# LKS32MC03x register map
Vendor: Linko Ltd.; Series: LKS32MC03x; File version: 1.0
CPU: CM0 r1p0, little endian, MPU, no FPU, 3 interrupt priority bits
Registers are 32-bit, read-write, reset 0x0 unless marked. A register's access mark holds for its fields unless they carry their own. Offsets are from the block's base; [hi:lo] are bit positions; {n}, {i} and the like mark numbered series.

## I2C — I2C registers
Base 0x40010100
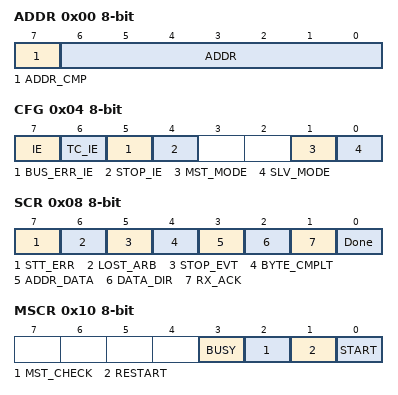
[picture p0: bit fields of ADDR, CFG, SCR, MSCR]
0x00 ADDR 8-bit — I2C Device Address
  [7] ADDR_CMP — i2c address compared by hardware control bit
    0=DISABLED (disable address compare by hardware); 1=ENABLED (enable address compare by hardware)
  [6:0] ADDR — i2c device address
0x04 CFG 8-bit — I2C Configuration
  [7] IE — i2c interrupt enable
    0=DISABLED (I2C interrupt is disabled); 1=ENABLED (I2C interrupt is enabled)
  [6] TC_IE — i2c transfer complete interrupt enable
    0=DISABLED (I2C transfer complete interrupt is disabled); 1=ENABLED (I2C transfer complete interrupt is enabled)
  [5] BUS_ERR_IE — i2c bus error interrupt control bit
    0=DISABLED (I2C bus error interrupt disable); 1=ENABLED (I2C bus error interrupt enable.only valid in master mode, master will release bus to idle state)
  [4] STOP_IE — i2c bus error interrupt control bit
    0=DISABLED (I2C stop interrupt is disabled); 1=ENABLED (I2C stop interrupt is enabled)
  [1] MST_MODE — i2c master mode control bit
    0=DISABLED (I2C master mode is disabled); 1=ENABLED (I2C master mode is enabled)
  [0] SLV_MODE — i2c slave mode control bit
    0=DISABLED (I2C slave mode is disabled); 1=ENABLED (I2C slave mode is enabled)
0x08 SCR 8-bit — I2C State_Control
  [7] STT_ERR — i2c master mode, check out error start/stop.read out 1 means error start/stop happened, write 0 to clear
  [6] LOST_ARB ro — i2c master mode, lost control of bus.i2c master mode, lost control of bus,set this bit to 1.write 0 to clear
  [5] STOP_EVT — i2c stop event happened.read out 1 means stop event happened, write 0 to clear
  [4] BYTE_CMPLT — receive mode, receive done, send ack/nack.receive done, this bit is set to 1 to send ack;set to 0 to send nack.
  [3] ADDR_DATA — addr/data.receive is address data, set to 1; data set to 0. write 0 to clear
  [2] DATA_DIR — send/receive mode select
    0=RX (receive mode); 1=TX (send mode)
  [1] RX_ACK — send mode, sent done, receive ack/nack. send done. receive ack,this bit is set to 1; nack, this bit is set to 0.write 0 to clear
  [0] Done ro — transmit done.current transmit done, set this bit to 1.write 0 to clear
0x0C DATA 8-bit — I2C Data Regsiter
  [7:0] DATA — i2c data.send mode, write; receive mode, read
0x10 MSCR 8-bit — I2C Master State_Control
  [3] BUSY ro — i2c busy/idle.bust start, set to 1; bus stop, set to 0
  [2] MST_CHECK ro — i2c device master mode feedback.i2c sends start, set this bit to 1, sends stop set this bit to 0.
  [1] RESTART — i2c generates restart signal.write 1 to generates restart signal, self clear.read out current state
  [0] START — i2c generates start signal.write 1 to generates start signal, self clear..read out current state
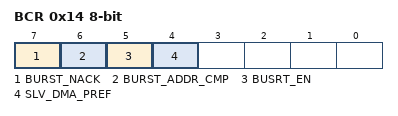
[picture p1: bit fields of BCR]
0x14 BCR 8-bit — I2C Burst Control
  [7] BURST_NACK — send mode, handle nack
    0=DISABLED (master is in send mode, return to stop. slave is in send mode, return to ilde); 1=ENABLED (generates nack interrupt, pulldown i2c clock bus.)
  [6] BURST_ADDR_CMP — address cmp by hardware, generate interrupt or not
    0=DISABLED (disable address compare by hardware in burst mode); 1=ENABLED (enable address compare by hardware in burst mode)
  [5] BUSRT_EN — Burst Mode Control Bit
    0=DISABLED (disable burst mode); 1=ENABLED (enable burst mode)
  [4] SLV_DMA_PREF — Slave DMA prefetch enable
    0=DISABLED (disable slave prefetch); 1=ENABLED (enable slave prefetch)
0x18 BSIZE 8-bit — DMA Length
  [4:0] BURST_SIZE

## CMP — CMP registers
Base 0x40010200
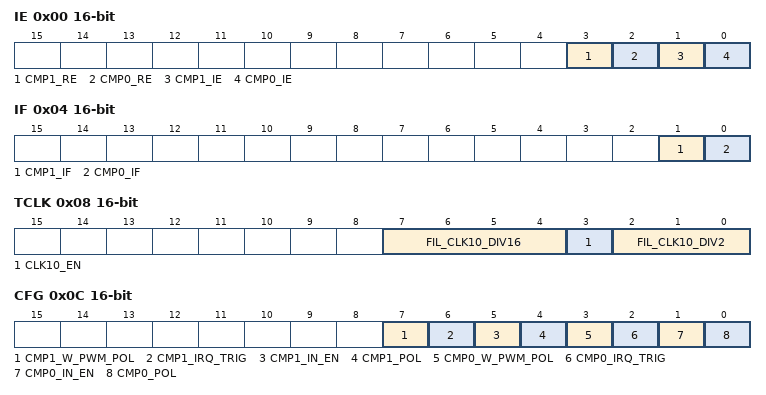
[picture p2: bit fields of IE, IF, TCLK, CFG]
0x00 IE 16-bit — Comparator interrupt enable
  [3] CMP1_RE — Comparator 1 DMA request enable
    0=DISABLED (Request disabled); 1=ENABLED (Request enabled)
  [2] CMP0_RE — Comparator 0 DMA request enable
    0=DISABLED (Request disabled); 1=ENABLED (Request enabled)
  [1] CMP1_IE — Comparator 1 interrupt enable
    0=DISABLED (irq disabled); 1=ENABLED (irq enabled)
  [0] CMP0_IE — Comparator 0 interrupt enable
    0=DISABLED (irq disabled); 1=ENABLED (irq enabled)
0x04 IF 16-bit — Comparator interrupt flag
  [1] CMP1_IF — Comparator 1 interrupt flag, write 1 to clear
  [0] CMP0_IF — Comparator 0 interrupt flag, write 1 to clear
0x08 TCLK 16-bit — Comparator clock division control
  [7:4] FIL_CLK10_DIV16 — Comparator 1/0 filter clock divided by 1~16
  [3] CLK10_EN — filter clock enable
  [2:0] FIL_CLK10_DIV2 — Comparator 1/0 filter clock divided by 2^n
    0=1DIV (no division); 1=2DIV (1/2 division); 2=4DIV (1/4 division); 3=8DIV (1/8 division); 4=16DIV (1/16 division); 5=32DIV (1/32 division); 6=64DIV (1/64 division); 7=128DIV (1/128 division)
0x0C CFG 16-bit — Comparator configuration
  [7] CMP1_W_PWM_POL — PWM signal polarity when used as Comparator 1 opening window contorl signal
  [6] CMP1_IRQ_TRIG — Comparator 1 irq trigger mechanism
    0=LEVEL_TRIG (Level trigger); 1=EDGE_TRIG (Edge trigger)
  [5] CMP1_IN_EN — Comparator 1 input enable
  [4] CMP1_POL — Comparator 1 polarity
    0=HIGH (high level effective); 1=LOW (low level effective)
  [3] CMP0_W_PWM_POL — PWM signal polarity when used as Comparator 0 opening window contorl signal
  [2] CMP0_IRQ_TRIG — Comparator 0 irq trigger mechanism
    0=LEVEL_TRIG (Level trigger); 1=EDGE_TRIG (Edge trigger)
  [1] CMP0_IN_EN — Comparator 0 input enable
  [0] CMP0_POL — Comparator 0 polarity
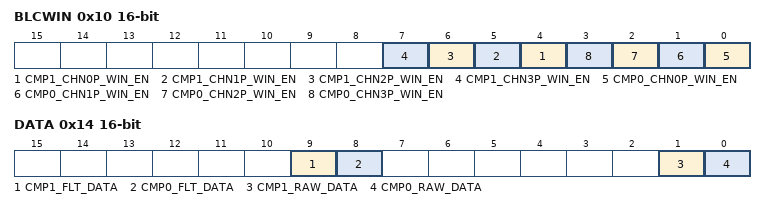
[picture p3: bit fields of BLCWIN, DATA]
0x10 BLCWIN 16-bit — Comparator black window control
  [n+4] CMP1_CHN{n}P_WIN_EN (n=0..3) — Comparator 1 black window controled by CHN{n}P enable
  [n] CMP0_CHN{n}P_WIN_EN (n=0..3) — Comparator 0 black window controled by CHN{n}P enable
0x14 DATA 16-bit ro — Comparator data
  [9] CMP1_FLT_DATA — Comparator 1 data after filter
  [8] CMP0_FLT_DATA — Comparator 0 data after filter
  [1] CMP1_RAW_DATA — Comparator 1 raw data
  [0] CMP0_RAW_DATA — Comparator 0 raw data

## Notices in the file
Copyright (C) 2012-2014 ARM Limited. All rights reserved.
Purpose: System Viewer Description (SVD) Example (Schema Version 1.1)
This is a description of a none-existent and incomplete device
for demonstration purposes only.
Redistribution and use in source and binary forms, with or without
modification, are permitted provided that the following conditions are met:
- Redistributions of source code must retain the above copyright
notice, this list of conditions and the following disclaimer.
- Redistributions in binary form must reproduce the above copyright
notice, this list of conditions and the following disclaimer in the
documentation and/or other materials provided with the distribution.
- Neither the name of ARM nor the names of its contributors may be used
to endorse or promote products derived from this software without
specific prior written permission.
THIS SOFTWARE IS PROVIDED BY THE COPYRIGHT HOLDERS AND CONTRIBUTORS "AS IS"
AND ANY EXPRESS OR IMPLIED WARRANTIES, INCLUDING, BUT NOT LIMITED TO, THE
IMPLIED WARRANTIES OF MERCHANTABILITY AND FITNESS FOR A PARTICULAR PURPOSE
ARE DISCLAIMED. IN NO EVENT SHALL COPYRIGHT HOLDERS AND CONTRIBUTORS BE
LIABLE FOR ANY DIRECT, INDIRECT, INCIDENTAL, SPECIAL, EXEMPLARY, OR
CONSEQUENTIAL DAMAGES (INCLUDING, BUT NOT LIMITED TO, PROCUREMENT OF
SUBSTITUTE GOODS OR SERVICES; LOSS OF USE, DATA, OR PROFITS; OR BUSINESS
INTERRUPTION) HOWEVER CAUSED AND ON ANY THEORY OF LIABILITY, WHETHER IN
CONTRACT, STRICT LIABILITY, OR TORT (INCLUDING NEGLIGENCE OR OTHERWISE)
ARISING IN ANY WAY OUT OF THE USE OF THIS SOFTWARE, EVEN IF ADVISED OF THE
POSSIBILITY OF SUCH DAMAGE.
